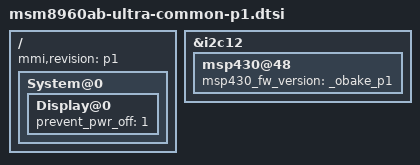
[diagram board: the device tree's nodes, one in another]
/* Copyright (c) 2013 Motorola Mobility LLC. All rights reserved.
 *
 * This program is free software; you can redistribute it and/or modify
 * it under the terms of the GNU General Public License version 2 and
 * only version 2 as published by the Free Software Foundation.
 *
 * This program is distributed in the hope that it will be useful,
 * but WITHOUT ANY WARRANTY; without even the implied warranty of
 * MERCHANTABILITY or FITNESS FOR A PARTICULAR PURPOSE.  See the
 * GNU General Public License for more details.
 */

/include/ "msm8960ab-ultra-common.dtsi"

/include/ "msm8960ab-ultra-p1-legacy.dtsi"

/ {
	mmi,revision = "p1";

	System@0 {
		Display@0 {
			prevent_pwr_off = <1>;
		};
	};
};

/* GSBI12 - I2C */
&i2c12 {
        msp430@48 {
                msp430_fw_version = "_obake_p1";
        };
};

